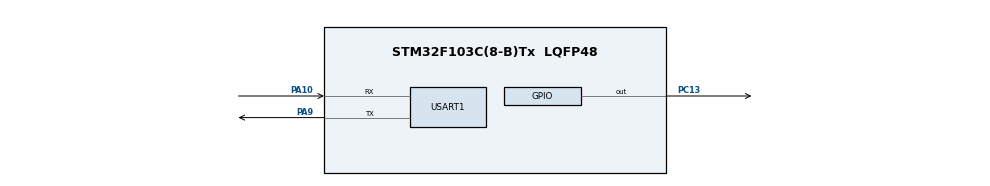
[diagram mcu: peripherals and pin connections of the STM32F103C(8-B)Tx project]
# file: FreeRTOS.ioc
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FREERTOS.Tasks01=Task1,0,128,task1EntryFunction,Default,NULL,Dynamic,NULL,NULL;task2,-3,128,task2EntryFunction,Default,NULL,Dynamic,NULL,NULL
FREERTOS.Timers01=myTimer01,Callback01,osTimerPeriodic,Default,NULL,Dynamic,NULL
FREERTOS.configTIMER_TASK_PRIORITY=3
FREERTOS.configTOTAL_HEAP_SIZE=8096
FREERTOS.configUSE_TIMERS=1
Mcu.Family=STM32F1
Mcu.Name=STM32F103C(8-B)Tx
Mcu.Package=LQFP48
NVIC.PriorityGroup=NVIC_PRIORITYGROUP_4
NVIC.TIM2_IRQn=true\:0\:0\:false\:false\:true\:false\:false\:true
NVIC.TimeBase=TIM2_IRQn
NVIC.TimeBaseIP=TIM2
NVIC.USART1_IRQn=true\:5\:0\:false\:false\:true\:true\:true\:true
PA10.Mode=Asynchronous
PA10.Signal=USART1_RX
PA9.Mode=Asynchronous
PA9.Signal=USART1_TX
PC13-TAMPER-RTC.Signal=GPIO_Output
PC14-OSC32_IN.Mode=LSE-External-Oscillator
PC14-OSC32_IN.Signal=RCC_OSC32_IN
PC15-OSC32_OUT.Mode=LSE-External-Oscillator
PC15-OSC32_OUT.Signal=RCC_OSC32_OUT
PD0-OSC_IN.Mode=HSE-External-Oscillator
PD0-OSC_IN.Signal=RCC_OSC_IN
PD1-OSC_OUT.Mode=HSE-External-Oscillator
PD1-OSC_OUT.Signal=RCC_OSC_OUT
ProjectManager.HeapSize=0x200
ProjectManager.StackSize=0x400
ProjectManager.TargetToolchain=TrueSTUDIO
RCC.APB1Freq_Value=8000000
RCC.APB2Freq_Value=8000000
USART1.VirtualMode=VM_ASYNC
VP_FREERTOS_VS_CMSIS_V1.Mode=CMSIS_V1
VP_SYS_VS_ND.Mode=No_Debug
VP_SYS_VS_tim2.Mode=TIM2
board=custom

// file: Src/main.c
/* USER CODE BEGIN Header */
/**
  ******************************************************************************
  * @file           : main.c
  * @brief          : Main program body
  ******************************************************************************
  * @attention
  *
  * <h2><center>&copy; Copyright (c) 2019 STMicroelectronics.
  * All rights reserved.</center></h2>
  *
  * This software component is licensed by ST under Ultimate Liberty license
  * SLA0044, the "License"; You may not use this file except in compliance with
  * the License. You may obtain a copy of the License at:
  *                             www.st.com/SLA0044
  *
  ******************************************************************************
  */
/* USER CODE END Header */

#include "main.h"
#include "cmsis_os.h"

/* USER CODE BEGIN PD */
#define TXSTARTMESSAGESIZE 				(COUNTOF(StartMessagge) - 1)
#define COUNTOF(__BUFFER__)   (sizeof(__BUFFER__) / sizeof(*(__BUFFER__)))

/* USER CODE END PD */

UART_HandleTypeDef huart1;

osThreadId Task1Handle;
osThreadId task2Handle;
osTimerId myTimer01Handle;
/* USER CODE BEGIN PV */
int TimerFlag = 1;
uint8_t StartMessagge[] = "\r\n Uart Ready: \r\n ";

/* USER CODE END PV */

void SystemClock_Config(void);
static void MX_GPIO_Init(void);
static void MX_USART1_UART_Init(void);
void task1EntryFunction(void const * argument);
void task2EntryFunction(void const * argument);
void Callback01(void const * argument);

int main(void)
{

  /* MCU Configuration--------------------------------------------------------*/

  /* Reset of all peripherals, Initializes the Flash interface and the Systick. */
  HAL_Init();

  /* Configure the system clock */
  SystemClock_Config();

  /* Initialize all configured peripherals */
  MX_GPIO_Init();
  MX_USART1_UART_Init();

  /* Create the timer(s) */
  /* definition and creation of myTimer01 */
  osTimerDef(myTimer01, Callback01);
  myTimer01Handle = osTimerCreate(osTimer(myTimer01), osTimerPeriodic, NULL);

  /* Create the thread(s) */
  /* definition and creation of Task1 */
  osThreadDef(Task1, task1EntryFunction, osPriorityNormal, 0, 128);
  Task1Handle = osThreadCreate(osThread(Task1), NULL);

  /* definition and creation of task2 */
  osThreadDef(task2, task2EntryFunction, osPriorityNormal, 0, 128);
  task2Handle = osThreadCreate(osThread(task2), NULL);

  /* Start scheduler */
  osKernelStart();

  /* We should never get here as control is now taken by the scheduler */

  /* Infinite loop */
  while (1)
  {

  }
}

void SystemClock_Config(void)
{
  RCC_OscInitTypeDef RCC_OscInitStruct = {0};
  RCC_ClkInitTypeDef RCC_ClkInitStruct = {0};

  /** Initializes the CPU, AHB and APB busses clocks
  */
  RCC_OscInitStruct.OscillatorType = RCC_OSCILLATORTYPE_HSI;
  RCC_OscInitStruct.HSIState = RCC_HSI_ON;
  RCC_OscInitStruct.HSICalibrationValue = RCC_HSICALIBRATION_DEFAULT;
  RCC_OscInitStruct.PLL.PLLState = RCC_PLL_NONE;
  if (HAL_RCC_OscConfig(&RCC_OscInitStruct) != HAL_OK)
  {
    Error_Handler();
  }
  /** Initializes the CPU, AHB and APB busses clocks
  */
  RCC_ClkInitStruct.ClockType = RCC_CLOCKTYPE_HCLK|RCC_CLOCKTYPE_SYSCLK
                              |RCC_CLOCKTYPE_PCLK1|RCC_CLOCKTYPE_PCLK2;
  RCC_ClkInitStruct.SYSCLKSource = RCC_SYSCLKSOURCE_HSI;
  RCC_ClkInitStruct.AHBCLKDivider = RCC_SYSCLK_DIV1;
  RCC_ClkInitStruct.APB1CLKDivider = RCC_HCLK_DIV1;
  RCC_ClkInitStruct.APB2CLKDivider = RCC_HCLK_DIV1;

  if (HAL_RCC_ClockConfig(&RCC_ClkInitStruct, FLASH_LATENCY_0) != HAL_OK)
  {
    Error_Handler();
  }
}

static void MX_USART1_UART_Init(void)
{

  huart1.Instance = USART1;
  huart1.Init.BaudRate = 115200;
  huart1.Init.WordLength = UART_WORDLENGTH_8B;
  huart1.Init.StopBits = UART_STOPBITS_1;
  huart1.Init.Parity = UART_PARITY_NONE;
  huart1.Init.Mode = UART_MODE_TX_RX;
  huart1.Init.HwFlowCtl = UART_HWCONTROL_NONE;
  huart1.Init.OverSampling = UART_OVERSAMPLING_16;
  if (HAL_UART_Init(&huart1) != HAL_OK)
  {
    Error_Handler();
  }

}

static void MX_GPIO_Init(void)
{
  GPIO_InitTypeDef GPIO_InitStruct = {0};

  /* GPIO Ports Clock Enable */
  __HAL_RCC_GPIOC_CLK_ENABLE();
  __HAL_RCC_GPIOD_CLK_ENABLE();
  __HAL_RCC_GPIOA_CLK_ENABLE();

  /*Configure GPIO pin Output Level */
  HAL_GPIO_WritePin(GPIOC, GPIO_PIN_13, GPIO_PIN_RESET);

  /*Configure GPIO pin : PC13 */
  GPIO_InitStruct.Pin = GPIO_PIN_13;
  GPIO_InitStruct.Mode = GPIO_MODE_OUTPUT_PP;
  GPIO_InitStruct.Pull = GPIO_NOPULL;
  GPIO_InitStruct.Speed = GPIO_SPEED_FREQ_LOW;
  HAL_GPIO_Init(GPIOC, &GPIO_InitStruct);

}

void task1EntryFunction(void const * argument)
{

  /* USER CODE BEGIN 5 */
  /* Infinite loop */
  for(;;)
  {
   HAL_UART_Transmit(&huart1, StartMessagge, TXSTARTMESSAGESIZE,10);
  }
  /* USER CODE END 5 */
}

void task2EntryFunction(void const * argument)
{
  /* USER CODE BEGIN task2EntryFunction */
  /* Infinite loop */
  for(;;)
  {
	if (TimerFlag == 1)
	{
		TimerFlag = 0;
		HAL_GPIO_TogglePin(GPIOC,GPIO_PIN_13);
		osTimerStart(myTimer01Handle, 1000);
		HAL_UART_Transmit(&huart1, StartMessagge, TXSTARTMESSAGESIZE,10);
	}

  }
  /* USER CODE END task2EntryFunction */
}

/* Callback01 function */
void Callback01(void const * argument)
{
  /* USER CODE BEGIN Callback01 */
  TimerFlag = 1;
  /* USER CODE END Callback01 */
}
void HAL_UART_RxCpltCallback(UART_HandleTypeDef *UartHandle)
{
	HAL_UART_Transmit_IT(&huart1, StartMessagge, TXSTARTMESSAGESIZE);
}
void HAL_TIM_PeriodElapsedCallback(TIM_HandleTypeDef *htim)
{
  if (htim->Instance == TIM2) {
    HAL_IncTick();
  }
}

void Error_Handler(void)
{
}

/************************ (C) COPYRIGHT STMicroelectronics *****END OF FILE****/
